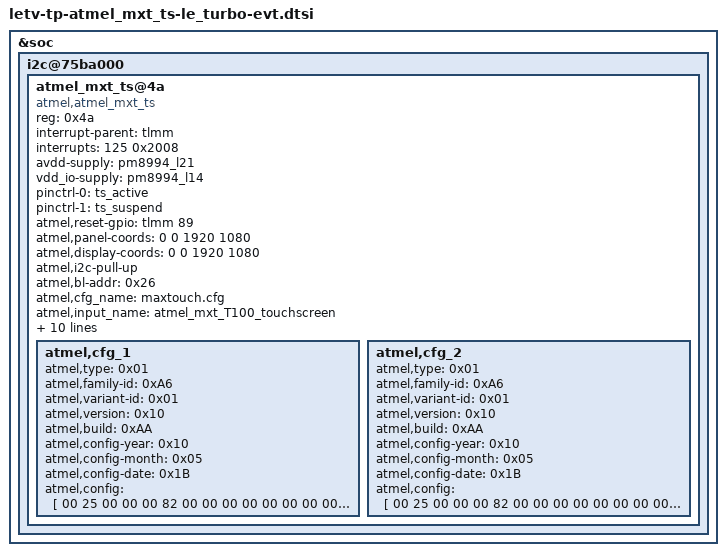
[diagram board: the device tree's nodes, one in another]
&soc {
	i2c@75ba000 {
		atmel_mxt_ts@4a {
			compatible = "atmel,atmel_mxt_ts";
			reg = <0x4a>;
			interrupt-parent = <&tlmm>;
			interrupts = <125 0x2008>;
			avdd-supply = <&pm8994_l21>;
			vdd_io-supply = <&pm8994_l14>;
			pinctrl-names = "pmx_ts_active", "pmx_ts_suspend";
			pinctrl-0 = <&ts_active>;
			pinctrl-1 = <&ts_suspend>;
			atmel,reset-gpio = <&tlmm 89 0>;
			atmel,panel-coords = <0 0 1920 1080>;
			atmel,display-coords = <0 0 1920 1080>;
			atmel,i2c-pull-up;
			atmel,bl-addr = <0x26>;
			atmel,cfg_name = "maxtouch.cfg";
			atmel,input_name = "atmel_mxt_T100_touchscreen";
			atmel,fw_version = "10AA";
			atmel,number-of-x-lines = <28>;
			atmel,number-of-y-lines = <16>;
			atmel,rawdata_threshold_max = <30500>;
			atmel,rawdata_threshold_min = <24500>;
			atmel,rawdata_shift_value = <4000>;
			atmel,rawdata_tkey_threshold_max = <26500>;
			atmel,rawdata_tkey_threshold_min = <21500>;
			atmel,rawdata_tkey_shift_value = <3500>;
			atmel,cap-button-codes = <0x244 172 158>;
			status = "ok";
			atmel,cfg_1 {
				atmel,type = <0x01>;
				atmel,family-id = <0xA6>;
				atmel,variant-id = <0x01>;
				atmel,version = <0x10>;
				atmel,build = <0xAA>;
				atmel,config-year = <0x10>;
				atmel,config-month = <0x05>;
				atmel,config-date = <0x1B>;
				atmel,config = [
					00 25 00 00 00 82 00 00
					00 00 00 00 00 00 00 00
					00 00 00 00 00 00 00 00
					00 00 00 00 00 00 00 00
					00 00 00 00 00 00 00 00
					00 00 00 00 00 00 00 00
					00 00 00 00 00 00 00 00
					00 00 00 00 00 00 00 00
					00 00 00 00 00 00 00 00
					00 00 00 00 00 00 00 00
					00 00 00 00 00 00 00 00
					00 00 00 00 00 00 00 00
					00 00 00 00 00 00 00 00
					00 00 00 00 00 00 00 00
					00 00 00 00 00 00 00 00
					00 00 00 00 00 00 00 00
					00 00 00 00 00 00 00 00
					00 05 00 00 00 0B FF 00
					00 00 00 00 00 00 00 00
					FF
					00 06 00 00 00 07 00 00
					00 00 00 00 00
					00 44 00 00 00 49 00 00
					00 00 00 00 00 00 00 00
					00 00 00 00 00 00 00 00
					00 00 00 00 00 00 00 00
					00 00 00 00 00 00 00 00
					00 00 00 00 00 00 00 00
					00 00 00 00 00 00 00 00
					00 00 00 00 00 00 00 00
					00 00 00 00 00 00 00 00
					00 00 00 00 00 00 00
					00 26 00 00 00 40 01 0A
					AA 10 05 1B 00 00 00 00
					00 00 00 00 00 00 00 00
					00 00 00 00 00 00 00 00
					00 00 00 00 00 00 00 00
					00 00 00 00 00 00 00 00
					00 00 00 00 00 00 00 00
					00 00 00 00 00 00 00 00
					00 00 00 00 00 00
					00 47 00 00 00 C8 00 00
					00 00 00 00 00 00 00 00
					00 00 00 00 00 00 00 00
					00 00 00 00 00 00 00 00
					00 00 00 00 00 00 00 00
					00 00 00 00 00 00 00 00
					00 00 00 00 00 00 00 00
					00 00 00 00 00 00 00 00
					00 00 00 00 00 00 00 00
					00 00 00 00 00 00 00 00
					00 00 00 00 00 00 00 00
					00 00 00 00 00 00 00 00
					00 00 00 00 00 00 00 00
					00 00 00 00 00 00 00 00
					00 00 00 00 00 00 00 00
					00 00 00 00 00 00 00 00
					00 00 00 00 00 00 00 00
					00 00 00 00 00 00 00 00
					00 00 00 00 00 00 00 00
					00 00 00 00 00 00 00 00
					00 00 00 00 00 00 00 00
					00 00 00 00 00 00 00 00
					00 00 00 00 00 00 00 00
					00 00 00 00 00 00 00 00
					00 00 00 00 00 00 00 00
					00 00 00 00 00 00
					00 6E 00 00 00 28 00 00
					00 00 00 00 00 00 00 00
					00 00 00 00 00 00 00 00
					00 00 00 00 00 00 00 00
					00 00 00 00 00 00 00 00
					00 00 00 00 00 00
					00 6E 00 01 00 28 00 00
					00 00 00 00 00 00 00 00
					00 00 00 00 00 00 00 00
					00 00 00 00 00 00 00 00
					00 00 00 00 00 00 00 00
					00 00 00 00 00 00
					00 6E 00 02 00 28 00 00
					00 00 00 00 00 00 00 00
					00 00 00 00 00 00 00 00
					00 00 00 00 00 00 00 00
					00 00 00 00 00 00 00 00
					00 00 00 00 00 00
					00 6E 00 03 00 28 00 00
					00 00 00 00 00 00 00 00
					00 00 00 00 00 00 00 00
					00 00 00 00 00 00 00 00
					00 00 00 00 00 00 00 00
					00 00 00 00 00 00
					00 6E 00 04 00 28 00 00
					00 00 00 00 00 00 00 00
					00 00 00 00 00 00 00 00
					00 00 00 00 00 00 00 00
					00 00 00 00 00 00 00 00
					00 00 00 00 00 00
					00 6E 00 05 00 28 00 00
					00 00 00 00 00 00 00 00
					00 00 00 00 00 00 00 00
					00 00 00 00 00 00 00 00
					00 00 00 00 00 00 00 00
					00 00 00 00 00 00
					00 6E 00 06 00 28 00 00
					00 00 00 00 00 00 00 00
					00 00 00 00 00 00 00 00
					00 00 00 00 00 00 00 00
					00 00 00 00 00 00 00 00
					00 00 00 00 00 00
					00 6E 00 07 00 28 00 00
					00 00 00 00 00 00 00 00
					00 00 00 00 00 00 00 00
					00 00 00 00 00 00 00 00
					00 00 00 00 00 00 00 00
					00 00 00 00 00 00
					00 6E 00 08 00 28 00 00
					00 00 00 00 00 00 00 00
					00 00 00 00 00 00 00 00
					00 00 00 00 00 00 00 00
					00 00 00 00 00 00 00 00
					00 00 00 00 00 00
					00 6E 00 09 00 28 00 00
					00 00 00 00 00 00 00 00
					00 00 00 00 00 00 00 00
					00 00 00 00 00 00 00 00
					00 00 00 00 00 00 00 00
					00 00 00 00 00 00
					00 6E 00 0A 00 28 00 00
					00 00 00 00 00 00 00 00
					00 00 00 00 00 00 00 00
					00 00 00 00 00 00 00 00
					00 00 00 00 00 00 00 00
					00 00 00 00 00 00
					00 6E 00 0B 00 28 00 00
					00 00 00 00 00 00 00 00
					00 00 00 00 00 00 00 00
					00 00 00 00 00 00 00 00
					00 00 00 00 00 00 00 00
					00 00 00 00 00 00
					00 07 00 00 00 05 FF FF
					32 00 00
					00 08 00 00 00 0F 32 00
					FF FF 00 00 FF 01 00 00
					01 01 01 01 00
					00 0F 00 00 00 0B 83 20
					00 01 03 00 06 3C 02 0F
					00
					00 12 00 00 00 02 00 00
					00 13 00 00 00 06 00 00
					00 00 00 00
					00 19 00 00 00 10 83 00
					00 00 00 00 00 00 00 00
					C8 00 00 00 00 00
					00 28 00 00 00 07 00 00
					00 00 00 00 00
					00 2A 00 00 00 0E 00 00
					00 00 00 00 00 00 00 00
					00 00 00 00
					00 2B 00 00 00 11 00 00
					00 00 00 00 00 00 00 00
					00 00 00 00 00 00 00
					00 2E 00 00 00 0C 04 00
					3F 3F 00 00 00 00 00 00
					00 00
					00 2F 00 00 00 2F 00 00
					00 00 00 00 00 00 00 00
					00 00 00 00 00 00 00 00
					00 00 00 00 00 00 00 00
					00 00 00 00 00 00 00 00
					00 00 00 00 00 00 00 00
					00 00 00 00 00
					00 38 00 00 00 24 00 00
					00 00 00 00 00 00 00 00
					00 00 00 00 00 00 00 00
					00 00 00 00 00 00 00 00
					00 00 00 00 00 00 00 00
					00 00
					00 3D 00 00 00 05 00 00
					00 00 00
					00 3D 00 01 00 05 00 00
					00 00 00
					00 3D 00 02 00 05 00 00
					00 00 00
					00 3D 00 03 00 05 00 00
					00 00 00
					00 3D 00 04 00 05 00 00
					00 00 00
					00 3D 00 05 00 05 00 00
					00 00 00
					00 41 00 00 00 17 81 08
					00 00 00 00 00 00 00 00
					04 00 00 00 00 00 00 11
					00 00 00 00 00
					00 41 00 01 00 17 00 00
					00 00 00 00 00 00 00 00
					00 00 00 00 00 00 00 00
					00 00 00 00 00
					00 41 00 02 00 17 00 00
					00 00 00 00 00 00 00 00
					00 00 00 00 00 00 00 00
					00 00 00 00 00
					00 46 00 00 00 0A 00 00
					00 00 00 00 00 00 00 00
					00 46 00 01 00 0A 00 00
					00 00 00 00 00 00 00 00
					00 46 00 02 00 0A 00 00
					00 00 00 00 00 00 00 00
					00 46 00 03 00 0A 00 00
					00 00 00 00 00 00 00 00
					00 46 00 04 00 0A 00 00
					00 00 00 00 00 00 00 00
					00 46 00 05 00 0A 00 00
					00 00 00 00 00 00 00 00
					00 46 00 06 00 0A 00 00
					00 00 00 00 00 00 00 00
					00 46 00 07 00 0A 00 00
					00 00 00 00 00 00 00 00
					00 46 00 08 00 0A 00 00
					00 00 00 00 00 00 00 00
					00 46 00 09 00 0A 00 00
					00 00 00 00 00 00 00 00
					00 46 00 0A 00 0A 00 00
					00 00 00 00 00 00 00 00
					00 46 00 0B 00 0A 00 00
					00 00 00 00 00 00 00 00
					00 46 00 0C 00 0A 00 00
					00 00 00 00 00 00 00 00
					00 46 00 0D 00 0A 00 00
					00 00 00 00 00 00 00 00
					00 46 00 0E 00 0A 00 00
					00 00 00 00 00 00 00 00
					00 46 00 0F 00 0A 00 00
					00 00 00 00 00 00 00 00
					00 46 00 10 00 0A 00 00
					00 00 00 00 00 00 00 00
					00 46 00 11 00 0A 00 00
					00 00 00 00 00 00 00 00
					00 46 00 12 00 0A 00 00
					00 00 00 00 00 00 00 00
					00 46 00 13 00 0A 00 00
					00 00 00 00 00 00 00 00
					00 48 00 00 00 59 00 00
					00 00 00 00 00 00 00 00
					00 00 00 00 00 00 00 00
					00 00 00 00 00 00 00 00
					00 00 00 00 00 00 00 00
					00 00 00 00 00 00 00 00
					00 00 00 00 00 00 00 00
					00 00 00 00 00 00 00 00
					00 00 00 00 00 00 00 00
					00 00 00 00 00 00 00 00
					00 00 00 00 00 00 00 00
					00 00 00 00 00 00 00
					00 4D 00 00 00 02 00 00
					00 4E 00 00 00 0C 00 00
					00 00 00 00 00 00 00 00
					00 00
					00 4F 00 00 00 04 00 00
					00 00
					00 4F 00 01 00 04 00 00
					00 00
					00 4F 00 02 00 04 00 00
					00 00
					00 50 00 00 00 0E 00 00
					00 00 00 00 00 00 00 00
					00 00 00 00
					00 51 00 00 00 12 00 00
					00 00 00 00 00 00 00 00
					00 00 00 00 00 00 00 00
					00 51 00 01 00 12 00 00
					00 00 00 00 00 00 00 00
					00 00 00 00 00 00 00 00
					00 5D 00 00 00 1E 00 00
					00 00 00 00 00 00 00 00
					00 00 00 00 00 00 00 00
					00 00 00 00 00 00 00 00
					00 00 00 00
					00 64 00 00 00 3E 8F A0
					00 17 00 00 0A 00 00 1C
					00 00 00 7F 07 00 00 00
					00 00 10 00 00 00 37 04
					00 00 0D 00 3C 0F 14 00
					00 32 00 0F 00 02 00 02
					00 0F 04 C8 30 0A 00 05
					00 00 00 05 00 00 00 00
					00 00 00 00
					00 68 00 00 00 0B 00 00
					00 00 00 00 00 00 00 00
					00
					00 6C 00 00 00 4B 00 00
					00 00 00 00 00 00 00 00
					00 00 00 00 00 00 00 00
					00 00 00 00 00 00 00 00
					00 00 00 00 00 00 00 00
					00 00 00 00 00 00 00 00
					00 00 00 00 00 00 00 00
					00 00 00 00 00 00 00 00
					00 00 00 00 00 00 00 00
					00 00 00 00 00 00 00 00
					00
					00 6D 00 00 00 09 00 00
					00 00 00 00 00 00 00
					00 6F 00 00 00 1E 00 00
					00 00 00 00 00 00 00 00
					00 00 00 00 00 00 00 00
					00 00 00 00 00 00 00 00
					00 00 00 00
					00 6F 00 01 00 1E 00 00
					00 00 00 00 00 00 00 00
					00 00 00 00 00 00 00 00
					00 00 00 00 00 00 00 00
					00 00 00 00
					00 70 00 00 00 05 00 00
					00 00 00
					00 71 00 00 00 03 00 00
					00
					00 73 00 00 00 14 00 00
					00 00 00 00 00 00 00 00
					00 00 00 00 00 00 00 00
					00 00
					00 74 00 00 00 FF 00 00
					00 00 00 00 00 00 00 00
					00 00 00 00 00 00 00 00
					00 00 00 00 00 00 00 00
					00 00 00 00 00 00 00 00
					00 00 00 00 00 00 00 00
					00 00 00 00 00 00 00 00
					00 00 00 00 00 00 00 00
					00 00 00 00 00 00 00 00
					00 00 00 00 00 00 00 00
					00 00 00 00 00 00 00 00
					00 00 00 00 00 00 00 00
					00 00 00 00 00 00 00 00
					00 00 00 00 00 00 00 00
					00 00 00 00 00 00 00 00
					00 00 00 00 00 00 00 00
					00 00 00 00 00 00 00 00
					00 00 00 00 00 00 00 00
					00 00 00 00 00 00 00 00
					00 00 00 00 00 00 00 00
					00 00 00 00 00 00 00 00
					00 00 00 00 00 00 00 00
					00 00 00 00 00 00 00 00
					00 00 00 00 00 00 00 00
					00 00 00 00 00 00 00 00
					00 00 00 00 00 00 00 00
					00 00 00 00 00 00 00 00
					00 00 00 00 00 00 00 00
					00 00 00 00 00 00 00 00
					00 00 00 00 00 00 00 00
					00 00 00 00 00 00 00 00
					00 00 00 00 00 00 00 00
					00 00 00 00 00
					00 79 00 00 00 03 00 00
					00
				];
			};
			atmel,cfg_2 {
				atmel,type = <0x01>;
				atmel,family-id = <0xA6>;
				atmel,variant-id = <0x01>;
				atmel,version = <0x10>;
				atmel,build = <0xAA>;
				atmel,config-year = <0x10>;
				atmel,config-month = <0x05>;
				atmel,config-date = <0x1B>;
				atmel,config = [
					00 25 00 00 00 82 00 00
					00 00 00 00 00 00 00 00
					00 00 00 00 00 00 00 00
					00 00 00 00 00 00 00 00
					00 00 00 00 00 00 00 00
					00 00 00 00 00 00 00 00
					00 00 00 00 00 00 00 00
					00 00 00 00 00 00 00 00
					00 00 00 00 00 00 00 00
					00 00 00 00 00 00 00 00
					00 00 00 00 00 00 00 00
					00 00 00 00 00 00 00 00
					00 00 00 00 00 00 00 00
					00 00 00 00 00 00 00 00
					00 00 00 00 00 00 00 00
					00 00 00 00 00 00 00 00
					00 00 00 00 00 00 00 00
					00 05 00 00 00 0B FF 00
					00 00 00 00 00 00 00 00
					FF
					00 06 00 00 00 07 00 00
					00 00 00 00 00
					00 44 00 00 00 49 00 00
					00 00 00 00 00 00 00 00
					00 00 00 00 00 00 00 00
					00 00 00 00 00 00 00 00
					00 00 00 00 00 00 00 00
					00 00 00 00 00 00 00 00
					00 00 00 00 00 00 00 00
					00 00 00 00 00 00 00 00
					00 00 00 00 00 00 00 00
					00 00 00 00 00 00 00
					00 26 00 00 00 40 01 0A
					AA 10 05 1B 00 00 00 00
					00 00 00 00 00 00 00 00
					00 00 00 00 00 00 00 00
					00 00 00 00 00 00 00 00
					00 00 00 00 00 00 00 00
					00 00 00 00 00 00 00 00
					00 00 00 00 00 00 00 00
					00 00 00 00 00 00
					00 47 00 00 00 C8 00 00
					00 00 00 00 00 00 00 00
					00 00 00 00 00 00 00 00
					00 00 00 00 00 00 00 00
					00 00 00 00 00 00 00 00
					00 00 00 00 00 00 00 00
					00 00 00 00 00 00 00 00
					00 00 00 00 00 00 00 00
					00 00 00 00 00 00 00 00
					00 00 00 00 00 00 00 00
					00 00 00 00 00 00 00 00
					00 00 00 00 00 00 00 00
					00 00 00 00 00 00 00 00
					00 00 00 00 00 00 00 00
					00 00 00 00 00 00 00 00
					00 00 00 00 00 00 00 00
					00 00 00 00 00 00 00 00
					00 00 00 00 00 00 00 00
					00 00 00 00 00 00 00 00
					00 00 00 00 00 00 00 00
					00 00 00 00 00 00 00 00
					00 00 00 00 00 00 00 00
					00 00 00 00 00 00 00 00
					00 00 00 00 00 00 00 00
					00 00 00 00 00 00 00 00
					00 00 00 00 00 00
					00 6E 00 00 00 28 00 00
					00 00 00 00 00 00 00 00
					00 00 00 00 00 00 00 00
					00 00 00 00 00 00 00 00
					00 00 00 00 00 00 00 00
					00 00 00 00 00 00
					00 6E 00 01 00 28 00 00
					00 00 00 00 00 00 00 00
					00 00 00 00 00 00 00 00
					00 00 00 00 00 00 00 00
					00 00 00 00 00 00 00 00
					00 00 00 00 00 00
					00 6E 00 02 00 28 00 00
					00 00 00 00 00 00 00 00
					00 00 00 00 00 00 00 00
					00 00 00 00 00 00 00 00
					00 00 00 00 00 00 00 00
					00 00 00 00 00 00
					00 6E 00 03 00 28 00 00
					00 00 00 00 00 00 00 00
					00 00 00 00 00 00 00 00
					00 00 00 00 00 00 00 00
					00 00 00 00 00 00 00 00
					00 00 00 00 00 00
					00 6E 00 04 00 28 00 00
					00 00 00 00 00 00 00 00
					00 00 00 00 00 00 00 00
					00 00 00 00 00 00 00 00
					00 00 00 00 00 00 00 00
					00 00 00 00 00 00
					00 6E 00 05 00 28 00 00
					00 00 00 00 00 00 00 00
					00 00 00 00 00 00 00 00
					00 00 00 00 00 00 00 00
					00 00 00 00 00 00 00 00
					00 00 00 00 00 00
					00 6E 00 06 00 28 00 00
					00 00 00 00 00 00 00 00
					00 00 00 00 00 00 00 00
					00 00 00 00 00 00 00 00
					00 00 00 00 00 00 00 00
					00 00 00 00 00 00
					00 6E 00 07 00 28 00 00
					00 00 00 00 00 00 00 00
					00 00 00 00 00 00 00 00
					00 00 00 00 00 00 00 00
					00 00 00 00 00 00 00 00
					00 00 00 00 00 00
					00 6E 00 08 00 28 00 00
					00 00 00 00 00 00 00 00
					00 00 00 00 00 00 00 00
					00 00 00 00 00 00 00 00
					00 00 00 00 00 00 00 00
					00 00 00 00 00 00
					00 6E 00 09 00 28 00 00
					00 00 00 00 00 00 00 00
					00 00 00 00 00 00 00 00
					00 00 00 00 00 00 00 00
					00 00 00 00 00 00 00 00
					00 00 00 00 00 00
					00 6E 00 0A 00 28 00 00
					00 00 00 00 00 00 00 00
					00 00 00 00 00 00 00 00
					00 00 00 00 00 00 00 00
					00 00 00 00 00 00 00 00
					00 00 00 00 00 00
					00 6E 00 0B 00 28 00 00
					00 00 00 00 00 00 00 00
					00 00 00 00 00 00 00 00
					00 00 00 00 00 00 00 00
					00 00 00 00 00 00 00 00
					00 00 00 00 00 00
					00 07 00 00 00 05 FF FF
					32 00 00
					00 08 00 00 00 0F 32 00
					FF FF 00 00 FF 01 00 00
					01 01 01 01 00
					00 0F 00 00 00 0B 83 20
					00 01 03 00 06 3C 02 0F
					00
					00 12 00 00 00 02 00 00
					00 13 00 00 00 06 00 00
					00 00 00 00
					00 19 00 00 00 10 83 00
					00 00 00 00 00 00 00 00
					C8 00 00 00 00 00
					00 28 00 00 00 07 00 00
					00 00 00 00 00
					00 2A 00 00 00 0E 00 00
					00 00 00 00 00 00 00 00
					00 00 00 00
					00 2B 00 00 00 11 00 00
					00 00 00 00 00 00 00 00
					00 00 00 00 00 00 00
					00 2E 00 00 00 0C 04 00
					3F 3F 00 00 00 00 00 00
					00 00
					00 2F 00 00 00 2F 00 00
					00 00 00 00 00 00 00 00
					00 00 00 00 00 00 00 00
					00 00 00 00 00 00 00 00
					00 00 00 00 00 00 00 00
					00 00 00 00 00 00 00 00
					00 00 00 00 00
					00 38 00 00 00 24 00 00
					00 00 00 00 00 00 00 00
					00 00 00 00 00 00 00 00
					00 00 00 00 00 00 00 00
					00 00 00 00 00 00 00 00
					00 00
					00 3D 00 00 00 05 00 00
					00 00 00
					00 3D 00 01 00 05 00 00
					00 00 00
					00 3D 00 02 00 05 00 00
					00 00 00
					00 3D 00 03 00 05 00 00
					00 00 00
					00 3D 00 04 00 05 00 00
					00 00 00
					00 3D 00 05 00 05 00 00
					00 00 00
					00 41 00 00 00 17 81 08
					00 00 00 00 00 00 00 00
					04 00 00 00 00 00 00 11
					00 00 00 00 00
					00 41 00 01 00 17 00 00
					00 00 00 00 00 00 00 00
					00 00 00 00 00 00 00 00
					00 00 00 00 00
					00 41 00 02 00 17 00 00
					00 00 00 00 00 00 00 00
					00 00 00 00 00 00 00 00
					00 00 00 00 00
					00 46 00 00 00 0A 00 00
					00 00 00 00 00 00 00 00
					00 46 00 01 00 0A 00 00
					00 00 00 00 00 00 00 00
					00 46 00 02 00 0A 00 00
					00 00 00 00 00 00 00 00
					00 46 00 03 00 0A 00 00
					00 00 00 00 00 00 00 00
					00 46 00 04 00 0A 00 00
					00 00 00 00 00 00 00 00
					00 46 00 05 00 0A 00 00
					00 00 00 00 00 00 00 00
					00 46 00 06 00 0A 00 00
					00 00 00 00 00 00 00 00
					00 46 00 07 00 0A 00 00
					00 00 00 00 00 00 00 00
					00 46 00 08 00 0A 00 00
					00 00 00 00 00 00 00 00
					00 46 00 09 00 0A 00 00
					00 00 00 00 00 00 00 00
					00 46 00 0A 00 0A 00 00
					00 00 00 00 00 00 00 00
					00 46 00 0B 00 0A 00 00
					00 00 00 00 00 00 00 00
					00 46 00 0C 00 0A 00 00
					00 00 00 00 00 00 00 00
					00 46 00 0D 00 0A 00 00
					00 00 00 00 00 00 00 00
					00 46 00 0E 00 0A 00 00
					00 00 00 00 00 00 00 00
					00 46 00 0F 00 0A 00 00
					00 00 00 00 00 00 00 00
					00 46 00 10 00 0A 00 00
					00 00 00 00 00 00 00 00
					00 46 00 11 00 0A 00 00
					00 00 00 00 00 00 00 00
					00 46 00 12 00 0A 00 00
					00 00 00 00 00 00 00 00
					00 46 00 13 00 0A 00 00
					00 00 00 00 00 00 00 00
					00 48 00 00 00 59 00 00
					00 00 00 00 00 00 00 00
					00 00 00 00 00 00 00 00
					00 00 00 00 00 00 00 00
					00 00 00 00 00 00 00 00
					00 00 00 00 00 00 00 00
					00 00 00 00 00 00 00 00
					00 00 00 00 00 00 00 00
					00 00 00 00 00 00 00 00
					00 00 00 00 00 00 00 00
					00 00 00 00 00 00 00 00
					00 00 00 00 00 00 00
					00 4D 00 00 00 02 00 00
					00 4E 00 00 00 0C 00 00
					00 00 00 00 00 00 00 00
					00 00
					00 4F 00 00 00 04 00 00
					00 00
					00 4F 00 01 00 04 00 00
					00 00
					00 4F 00 02 00 04 00 00
					00 00
					00 50 00 00 00 0E 00 00
					00 00 00 00 00 00 00 00
					00 00 00 00
					00 51 00 00 00 12 00 00
					00 00 00 00 00 00 00 00
					00 00 00 00 00 00 00 00
					00 51 00 01 00 12 00 00
					00 00 00 00 00 00 00 00
					00 00 00 00 00 00 00 00
					00 5D 00 00 00 1E 00 00
					00 00 00 00 00 00 00 00
					00 00 00 00 00 00 00 00
					00 00 00 00 00 00 00 00
					00 00 00 00
					00 64 00 00 00 3E 8F A0
					00 17 00 00 0A 00 00 1C
					00 00 00 7F 07 00 00 00
					00 00 10 00 00 00 37 04
					00 00 0D 00 3C 0F 14 00
					00 32 00 0F 00 02 00 02
					00 0F 04 C8 30 0A 00 05
					00 00 00 05 00 00 00 00
					00 00 00 00
					00 68 00 00 00 0B 00 00
					00 00 00 00 00 00 00 00
					00
					00 6C 00 00 00 4B 00 00
					00 00 00 00 00 00 00 00
					00 00 00 00 00 00 00 00
					00 00 00 00 00 00 00 00
					00 00 00 00 00 00 00 00
					00 00 00 00 00 00 00 00
					00 00 00 00 00 00 00 00
					00 00 00 00 00 00 00 00
					00 00 00 00 00 00 00 00
					00 00 00 00 00 00 00 00
					00
					00 6D 00 00 00 09 00 00
					00 00 00 00 00 00 00
					00 6F 00 00 00 1E 00 00
					00 00 00 00 00 00 00 00
					00 00 00 00 00 00 00 00
					00 00 00 00 00 00 00 00
					00 00 00 00
					00 6F 00 01 00 1E 00 00
					00 00 00 00 00 00 00 00
					00 00 00 00 00 00 00 00
					00 00 00 00 00 00 00 00
					00 00 00 00
					00 70 00 00 00 05 00 00
					00 00 00
					00 71 00 00 00 03 00 00
					00
					00 73 00 00 00 14 00 00
					00 00 00 00 00 00 00 00
					00 00 00 00 00 00 00 00
					00 00
					00 74 00 00 00 FF 00 00
					00 00 00 00 00 00 00 00
					00 00 00 00 00 00 00 00
					00 00 00 00 00 00 00 00
					00 00 00 00 00 00 00 00
					00 00 00 00 00 00 00 00
					00 00 00 00 00 00 00 00
					00 00 00 00 00 00 00 00
					00 00 00 00 00 00 00 00
					00 00 00 00 00 00 00 00
					00 00 00 00 00 00 00 00
					00 00 00 00 00 00 00 00
					00 00 00 00 00 00 00 00
					00 00 00 00 00 00 00 00
					00 00 00 00 00 00 00 00
					00 00 00 00 00 00 00 00
					00 00 00 00 00 00 00 00
					00 00 00 00 00 00 00 00
					00 00 00 00 00 00 00 00
					00 00 00 00 00 00 00 00
					00 00 00 00 00 00 00 00
					00 00 00 00 00 00 00 00
					00 00 00 00 00 00 00 00
					00 00 00 00 00 00 00 00
					00 00 00 00 00 00 00 00
					00 00 00 00 00 00 00 00
					00 00 00 00 00 00 00 00
					00 00 00 00 00 00 00 00
					00 00 00 00 00 00 00 00
					00 00 00 00 00 00 00 00
					00 00 00 00 00 00 00 00
					00 00 00 00 00 00 00 00
					00 00 00 00 00
					00 79 00 00 00 03 00 00
					00
				];
			};
		};
	};
};
